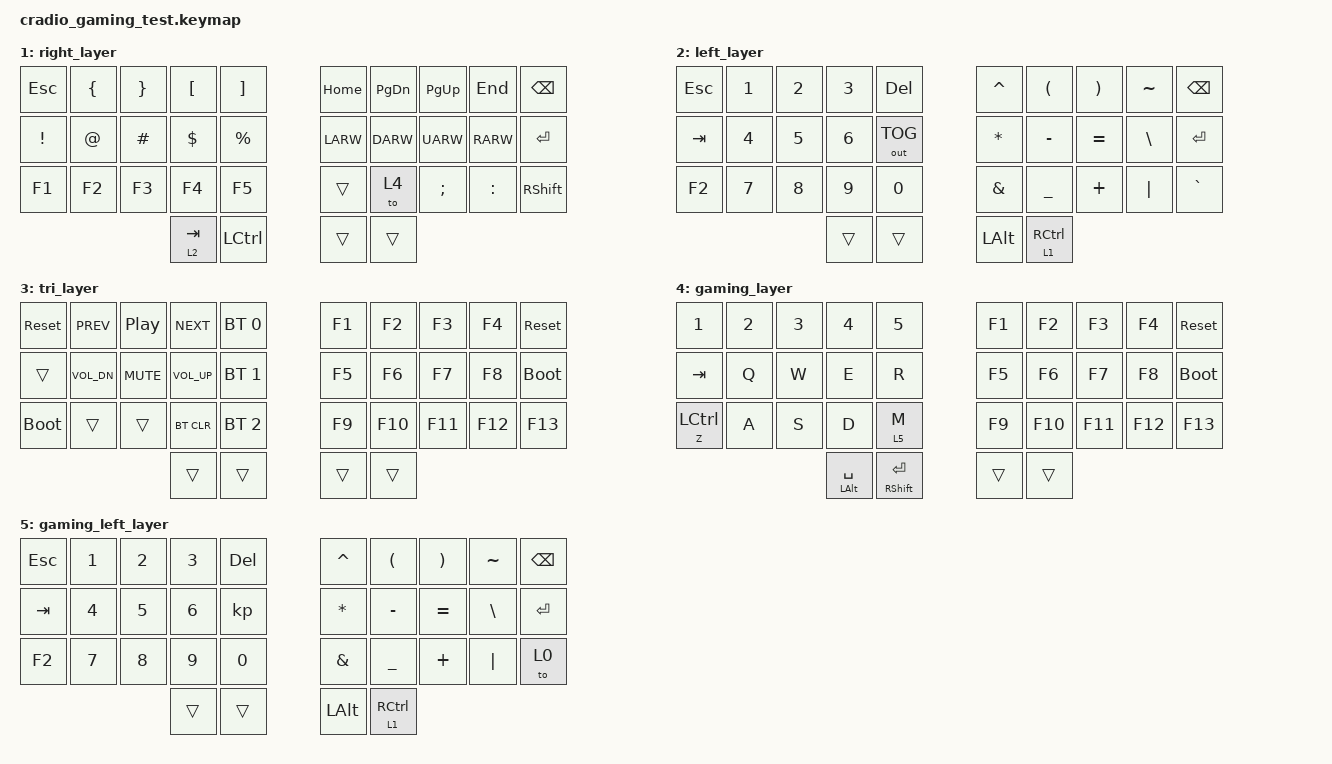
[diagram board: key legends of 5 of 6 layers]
// Copyright (c) 2022 The ZMK Contributors
// SPDX-License-Identifier: MIT

#include <behaviors.dtsi>
#include <dt-bindings/zmk/keys.h>
#include <dt-bindings/zmk/bt.h>
#include <dt-bindings/zmk/outputs.h>

// Home row mods macro
#define HRML(k1,k2,k3,k4) &ht LSHFT k1  &ht LALT k2  &ht LCTRL k3  &ht LGUI k4
#define HRMR(k1,k2,k3,k4) &ht RGUI k1  &ht RCTRL k2  &ht LALT k3  &ht RSHFT k4

/ {
    behaviors {
        ht: hold_tap {
            label = "hold_tap";
            compatible = "zmk,behavior-hold-tap";
            #binding-cells = <2>;
            flavor = "tap-preferred";
            tapping-term-ms = <220>;
            quick-tap-ms = <150>;
            global-quick-tap;
            bindings = <&kp>, <&kp>;
        };
        td: tapdance {
            compatible = "zmk,behavior-hold-tap";
            label = "TAPDANCE";
            #binding-cells = <2>;
            tapping-term-ms = <150>;
            quick_tap_ms = <0>;
            flavor = "tap-preferred";
            bindings = <&kp>, <&kp>;
        };
    };

    conditional_layers {
        compatible = "zmk,conditional-layers";
        tri_layer {
            if-layers = <1 2>;
            then-layer = <3>;
        };
    };

    keymap {
        compatible = "zmk,keymap";
        default_layer {
            bindings = <
        //╭──────────┬──────────┬──────────┬──────────┬──────────╮   ╭──────────┬──────────┬──────────┬──────────┬──────────╮
        //│  Q       │  W       │  E       │  R       │  T       │   │  Y       │  U       │  I       │  O       │  P       │
            &kp Q      &kp W      &kp E      &kp R      &kp T          &kp Y      &kp U      &kp I      &kp O      &kp P
        //├──────────┼──────────┼──────────┼──────────┼──────────┤   ├──────────┼──────────┼──────────┼──────────┼──────────┤
        //│  A       │  S       │  D       │  F       │  G       │   │  H       │  J       │  K       │  L       │ ' "      │
            HRML(A,        S,         D,         F)     &kp G          &kp H      HRMR(J,        K,         L,        SQT)
        //├──────────┼──────────┼──────────┼──────────┼──────────┤   ├──────────┼──────────┼──────────┼──────────┼──────────┤
        //│  Z       │  X       │  C       │  V       │  B       │   │  N       │  M       │ , <      │ . >      │ / ?      │
            &kp Z      &kp X      &kp C      &kp V      &kp B          &kp N      &kp M      &kp COMMA  &kp DOT    &kp FSLH
        //╰──────────┴──────────┴──────────┼──────────┼──────────┤   ├──────────┼──────────┼──────────┴──────────┴──────────╯
                                         &lt 2 TAB  &td LCTRL ENTER &td RSHFT SPACE  &lt 1 BSPC
        //                                 ╰──────────┴──────────╯   ╰──────────┴──────────╯
            >;
        };

        right_layer {
            bindings = <
        //╭──────────┬──────────┬──────────┬──────────┬──────────╮   ╭──────────┬──────────┬──────────┬──────────┬──────────╮
        //│ ESC      │  {       │  }       │  [       │  ]       │   │ HOME     │ PAGE DN  │ PAGE UP  │ END      │  BSPC    │
            &kp ESC    &kp LBRC   &kp RBRC   &kp LBKT   &kp RBKT        &kp HOME   &kp PG_DN  &kp PG_UP  &kp END    &kp BSPC 
        //├──────────┼──────────┼──────────┼──────────┼──────────┤   ├──────────┼──────────┼──────────┼──────────┼──────────┤
        //│  !       │  @       │  #       │  $       │  %       │   │ LEFT     │ DOWN     │ UP       │ RIGHT    │  ENTER   │
            &kp EXCL   &kp AT     &kp HASH   &kp DLLR   &kp PRCNT      &kp LARW   &kp DARW   &kp UARW   &kp RARW   &kp ENTER
        //├──────────┼──────────┼──────────┼──────────┼──────────┤   ├──────────┼──────────┼──────────┼──────────┼──────────┤
        //│          │          │          │          │          │   │          │Gaming L  │  ;       │  :       │          │
            &kp F1     &kp F2     &kp F3     &kp F4     &kp F5         &trans     &to 4      &kp SEMI   &kp COLON  &kp RSHFT
        //╰──────────┴──────────┴──────────┼──────────┼──────────┤   ├──────────┼──────────┼──────────┴──────────┴──────────╯
                                             &lt 2 TAB  &kp LCTRL      &trans     &trans
        //                                 ╰──────────┴──────────╯   ╰──────────┴──────────╯
            >;
        };

        left_layer {
            bindings = <
        //╭──────────┬──────────┬──────────┬──────────┬──────────╮   ╭──────────┬──────────┬──────────┬──────────┬──────────╮
        //│ ESC      │  1       │  2       │  3       │ DELETE   │   │  ^       │  (       │  )       │  ~       │  BSPC    │
            &kp ESC    &kp N1     &kp N2     &kp N3     &kp DEL        &kp CARET  &kp LPAR   &kp RPAR   &kp TILDE  &kp BSPC 
        //├──────────┼──────────┼──────────┼──────────┼──────────┤   ├──────────┼──────────┼──────────┼──────────┼──────────┤
        //│ TAB      │  4       │  5       │  6       │ USB/BLE  │   │  *       │  -       │  =       │  \       │ ENTER    │
            &kp TAB    &kp N4     &kp N5     &kp N6     &out OUT_TOG   &kp ASTRK  &kp MINUS  &kp EQUAL  &kp BSLH   &kp ENTER
        //├──────────┼──────────┼──────────┼──────────┼──────────┤   ├──────────┼──────────┼──────────┼──────────┼──────────┤
        //│          │  7       │  8       │  9       │  0       │   │  &       │  _       │  +       │  │       │  `       │
            &kp F2     &kp N7     &kp N8     &kp N9     &kp N0         &kp AMPS   &kp UNDER  &kp PLUS   &kp PIPE   &kp GRAVE
        //╰──────────┴──────────┴──────────┼──────────┼──────────┤   ├──────────┼──────────┼──────────┴──────────┴──────────╯
                                             &trans     &trans         &kp LALT   &lt 1 RCTRL
        //                                 ╰──────────┴──────────╯   ╰──────────┴──────────╯
            >;
        };

        tri_layer {
            bindings = <
        //╭──────────┬──────────┬──────────┬──────────┬──────────╮   ╭──────────┬──────────┬──────────┬──────────┬──────────╮
        //│ RESET    │          │          │          │PROFILE 0 │   │          │          │          │          │  RESET   │
           &sys_reset &kp C_PREV &kp C_PP   &kp C_NEXT &bt BT_SEL 0    &kp F1     &kp F2     &kp F3     &kp F4    &sys_reset
        //├──────────┼──────────┼──────────┼──────────┼──────────┤   ├──────────┼──────────┼──────────┼──────────┼──────────┤
        //│          │          │          │          │PROFILE 1 │   │          │          │          │          │BOOTLOADER│
            &trans   &kp C_VOL_DN &kp C_MUTE &kp C_VOL_UP &bt BT_SEL 1 &kp F5    &kp F6     &kp F7     &kp F8    &bootloader
        //├──────────┼──────────┼──────────┼──────────┼──────────┤   ├──────────┼──────────┼──────────┼──────────┼──────────┤
        //│BOOTLOADER│          │          │ CLEAR BT │PROFILE 2 │   │          │          │          │          │          │
          &bootloader   &trans     &trans    &bt BT_CLR &bt BT_SEL 2    &kp F9     &kp F10    &kp F11    &kp F12    &kp F13
        //╰──────────┴──────────┴──────────┼──────────┼──────────┤   ├──────────┼──────────┼──────────┴──────────┴──────────╯
                                             &trans     &trans         &trans     &trans
        //                                 ╰──────────┴──────────╯   ╰──────────┴──────────╯
            >;
        };

        gaming_layer {
            bindings = <
        //╭──────────┬──────────┬──────────┬──────────┬──────────╮   ╭──────────┬──────────┬──────────┬──────────┬──────────╮
        //│    1     │    2     │    3     │    4     │    5     │   │          │          │          │          │          │
            &kp N1     &kp N2     &kp N3     &kp N4     &kp N5         &kp F1     &kp F2     &kp F3     &kp F4    &sys_reset
        //├──────────┼──────────┼──────────┼──────────┼──────────┤   ├──────────┼──────────┼──────────┼──────────┼──────────┤
        //│  TAB     │    Q     │    W     │    E     │    R     │   │          │          │          │          │          │
           &kp TAB     &kp Q      &kp W      &kp E      &kp R          &kp F5    &kp F6     &kp F7     &kp F8    &bootloader
        //├──────────┼──────────┼──────────┼──────────┼──────────┤   ├──────────┼──────────┼──────────┼──────────┼──────────┤
        //│  CTRL    │    A     │    S     │    D     │ Layer GL │   │          │          │          │          │          │
          &td Z LCTRL  &kp A      &kp S      &kp D      &lt 5 M        &kp F9     &kp F10    &kp F11    &kp F12    &kp F13
        //╰──────────┴──────────┴──────────┼──────────┼──────────┤   ├──────────┼──────────┼──────────┴──────────┴──────────╯
                                       &td LALT SPACE  &td RSHFT ENTER     &trans     &trans
        //                                 ╰──────────┴──────────╯   ╰──────────┴──────────╯
            >;
        };

        gaming_left_layer {
            bindings = <
        //╭──────────┬──────────┬──────────┬──────────┬──────────╮   ╭──────────┬──────────┬──────────┬──────────┬──────────╮
        //│ ESC      │  I       │  L       │  K       │   T      │   │  ^       │  (       │  )       │  ~       │  BSPC    │
            &kp ESC    &kp N1     &kp N2     &kp N3     &kp DEL        &kp CARET  &kp LPAR   &kp RPAR   &kp TILDE  &kp BSPC 
        //├──────────┼──────────┼──────────┼──────────┼──────────┤   ├──────────┼──────────┼──────────┼──────────┼──────────┤
        //│  AB      │  T       │  SHFT L  │  O       │          │   │  *       │  -       │  =       │  \       │ ENTER    │
            &kp TAB    &kp N4     &kp N5     &kp N6     &kp            &kp ASTRK  &kp MINUS  &kp EQUAL  &kp BSLH   &kp ENTER
        //├──────────┼──────────┼──────────┼──────────┼──────────┤   ├──────────┼──────────┼──────────┼──────────┼──────────┤
        //│  SHFT    │  SHFT I  │  C       │  V       │  0       │   │  &       │  _       │  +       │  │       │ Def Layer│
            &kp F2     &kp N7     &kp N8     &kp N9     &kp N0         &kp AMPS   &kp UNDER  &kp PLUS   &kp PIPE   &to 0    
        //╰──────────┴──────────┴──────────┼──────────┼──────────┤   ├──────────┼──────────┼──────────┴──────────┴──────────╯
                                             &trans     &trans         &kp LALT   &lt 1 RCTRL
        //                                 ╰──────────┴──────────╯   ╰──────────┴──────────╯
            >;
        };
    };
};
